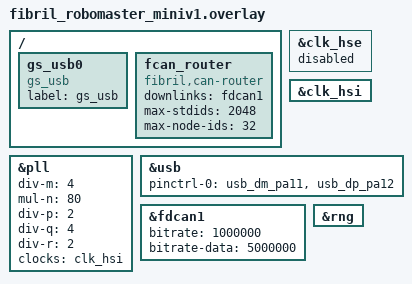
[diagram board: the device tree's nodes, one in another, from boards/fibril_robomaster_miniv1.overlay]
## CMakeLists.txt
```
# SPDX-License-Identifier: Apache-2.0
#
# Zephyr sample: fibril_can router + latency-probe self node driven over
# CANnectivity's gs_usb uplink. Same wire contract as
# fibril_zephyr/samples/lib/fibril_can/latency_probe_node, but the probe self
# node sits inside a fcan_router device — uplink is USB (gs_usb) and downlink
# is fdcan1. Use this variant when the same MCU also has to gateway a
# physical CAN bus to the host.
#
# Prerequisites: see the fibril_can module's zephyr/cmake/fcan_invoke_codegen.cmake
# for the fcan_codegen CLI resolution.

cmake_minimum_required(VERSION 3.20.0)
find_package(Zephyr REQUIRED HINTS $ENV{ZEPHYR_BASE})

project(fibril_can_router_gs_usb_latency_probe LANGUAGES C)

if(NOT ZEPHYR_FIBRIL_CAN_MODULE_DIR)
  message(FATAL_ERROR
    "ZEPHYR_FIBRIL_CAN_MODULE_DIR is not set — is the fibril_can module on "
    "the west manifest and is CONFIG_FIBRIL_CAN=y?")
endif()

include(${ZEPHYR_FIBRIL_CAN_MODULE_DIR}/zephyr/cmake/fcan_invoke_codegen.cmake)

set(FCAN_LATENCY_PROBE_SCHEMA
  "${ZEPHYR_FIBRIL_CAN_MODULE_DIR}/fibril_can_benchmark/schema/latency_probe.yaml"
  CACHE FILEPATH "Schema YAML to feed into fcan_codegen")

fcan_invoke_codegen(
  SCHEMA     "${FCAN_LATENCY_PROBE_SCHEMA}"
  OUTPUT_DIR "${CMAKE_CURRENT_BINARY_DIR}/schema_gen"
  BASE_NAME  schema_gen)

target_sources(app PRIVATE
  src/main.c
  src/probe_logic.c
  src/usbd_setup.c)

target_include_directories(app PRIVATE
  ${CMAKE_CURRENT_SOURCE_DIR}/src)
```

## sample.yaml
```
sample:
  name: fibril_can router + latency-probe self via CANnectivity gs_usb uplink
  description: >-
    fibril_can_benchmark latency-probe firmware wired into a fcan_router self
    node. The router uplink is CANnectivity's gs_usb device class (USB), so
    the host PC opens one SocketCAN interface and the ROS probe launch talks
    to the self node through it. The downlink (fdcan1) stays available for
    real slaves on a physical CAN bus. Same on-wire contract as
    samples/lib/fibril_can/latency_probe_node, but placed at the router
    uplink instead of a bare CAN interface — see firmware-requirements §8.

tests:
  sample.lib.fibril_can.router_gs_usb_latency_probe:
    tags:
      - fibril_can
      - fibril_can_benchmark
      - can
      - router
      - usb
    filter: CONFIG_FIBRIL_CAN and dt_compat_enabled("fibril,can-router") and dt_compat_enabled("gs_usb")
    harness: console
    harness_config:
      type: multi_line
      ordered: true
      regex:
        - "fcan_router_latency_probe: fcan_init OK"
        - "fcan_router_latency_probe: fcan_router_attach_self OK"
        - "fcan_router_latency_probe: fcan_register_all OK"
        - "fcan_router_latency_probe: gs_usb_register OK"
        - "fcan_router_latency_probe: usbd_enable OK"
        - "fcan_router_latency_probe: entering main loop"
    integration_platforms:
      - fibril_robomaster_miniv1
    # Twister needs to know where fcan_codegen lives before it can build this
    # sample. Set FCAN_CODEGEN in the environment before invoking twister:
    #   FCAN_CODEGEN=/abs/path/fcan_codegen twister -T fibril_zephyr/samples/lib/fibril_can/router_gs_usb_latency_probe
    # or pass --extra-args=-DFCAN_CODEGEN=... to twister directly.
```

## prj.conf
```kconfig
# SPDX-License-Identifier: Apache-2.0

# --- fibril_can slave runtime + router driver
CONFIG_FIBRIL_CAN=y
CONFIG_CAN=y
CONFIG_CAN_FD_MODE=y
CONFIG_CAN_FCAN_ROUTER=y

# --- event-driven scheduler wake for fcan_zephyr_can_hal. This sample drives
#     fcan_poll(self) through the router thread (no fcan_zephyr_can_hal
#     instance), so the option has no runtime effect here; kept aligned with
#     the other fibril_can samples so the switch is uniform across the tree.
CONFIG_FCAN_ZEPHYR_EVENT_WAKE=y

# --- Router poll cadence. Default 1000 µs bounds the change-driven echo dwell
#     between "commit" (main thread) and "emit" (router thread) — see the
#     README's "latency components" section. Lowering this reduces average
#     dwell at the cost of CPU spent on empty polls; the effective resolution
#     floor is one SYS_CLOCK_TICKS_PER_SEC tick (100 µs at 10 kHz).
CONFIG_CAN_FCAN_ROUTER_POLL_INTERVAL_US=1000

# --- entropy for boot_id (SPEC §5.3 T_listen jitter seed).
CONFIG_ENTROPY_GENERATOR=y

# --- runtime allocation. K_HEAP_DEFINE in main.c carves its own arena, but
#     leave a small system heap for the CAN / USB / RNG drivers.
CONFIG_HEAP_MEM_POOL_SIZE=4096
CONFIG_MAIN_STACK_SIZE=4096

# --- kernel tick precision. 10 kHz keeps the main tick jitter within the
#     §5 hot-path budget (echo commit dwell ≤ 100 μs @ 1 kHz tick).
CONFIG_SYS_CLOCK_TICKS_PER_SEC=10000

# --- USB device stack next + CANnectivity's gs_usb class. CONFIG_USBD_GS_USB
#     defaults to y whenever a "gs_usb" DT node is enabled, but state it
#     explicitly so the sample's intent is grep-able.
CONFIG_USB_DEVICE_STACK_NEXT=y
CONFIG_USBD_GS_USB=y

# Quieter USB stack — switch the two lines below to _DBG when debugging USB
# enumeration failures on real hardware.
CONFIG_UDC_DRIVER_LOG_LEVEL_WRN=y
CONFIG_USBD_LOG_LEVEL_WRN=y
CONFIG_USBD_GS_USB_LOG_LEVEL_INF=y

# --- logging: no LOG in the hot path (status thread only), so IMMEDIATE
#     mode is safe.
CONFIG_LOG=y
CONFIG_LOG_MODE_IMMEDIATE=y
CONFIG_BOOT_BANNER=y
```

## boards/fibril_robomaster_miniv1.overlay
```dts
/*
 * SPDX-License-Identifier: Apache-2.0
 *
 * router+latency-probe self+gs_usb sample on the Fibril RoboMaster Mini V1.
 *   uplink   = USB FS (PA11/PA12) -> gs_usb subsys -> fcan_router device
 *   downlink = FDCAN1 (PD0/PD1)   (board DTS already sets pinctrl + PLL_Q clock)
 *
 * Mirrors samples/lib/fibril_can/router_gs_usb_self.overlay so both samples
 * share the same host udev/gs_usb setup — see that overlay's comments for
 * the HSI16/PLL rationale. Only the compatible strings and app source
 * differ between the two samples.
 */

/ {
	gs_usb0: gs_usb0 {
		compatible = "gs_usb";
		label = "gs_usb";
	};

	fcan_router: fcan_router {
		compatible = "fibril,can-router";
		status = "okay";
		downlinks = <&fdcan1>;
		/* std_id 学習テーブルの幅。fibril_can_bridge の StdIdAllocator は
		 * 0x100 (256) から発番するので、max-stdids は必ず 0x100 より
		 * 大きい必要がある。DT binding のデフォルト 2048 (= 11-bit CAN
		 * ID 全域) を使う。stdid_mask はエントリあたり 1 バイトなので
		 * 2 KiB。H723 の RAM 予算では誤差。 */
		max-stdids = <2048>;
		max-node-ids = <32>;
	};
};

&clk_hse {
	status = "disabled";
};

&clk_hsi {
	status = "okay";
};

&pll {
	div-m = <4>;
	mul-n = <80>;
	div-p = <2>;
	div-q = <4>;
	div-r = <2>;
	clocks = <&clk_hsi>;
	status = "okay";
};

zephyr_udc0: &usb {
	pinctrl-0 = <&usb_dm_pa11 &usb_dp_pa12>;
	pinctrl-names = "default";
	status = "okay";
};

&fdcan1 {
	/* 1 Mbps arbitration / 5 Mbps FD data phase — matches the single-bus
	 * latency_probe_node sample so wire timings are directly comparable. */
	bitrate = <1000000>;
	bitrate-data = <5000000>;
	status = "okay";
};

&rng {
	status = "okay";
};
```

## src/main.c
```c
/*
 * SPDX-License-Identifier: Apache-2.0
 *
 * Zephyr entry point for the fibril_can router + latency-probe self node +
 * gs_usb sample. Cross-references:
 *
 *   fibril_can_benchmark/docs/firmware-requirements.md — wire contract
 *   fibril_can/docs/09-router.md                        — router lifecycle
 *   samples/lib/fibril_can/router_gs_usb_self           — non-benchmark twin
 *   samples/lib/fibril_can/latency_probe_node           — single-bus twin
 *
 * Threading model
 * ---------------
 * The router driver thread owns fcan_router_on_rx() and calls
 * fcan_poll(self) at CONFIG_CAN_FCAN_ROUTER_POLL_INTERVAL_US granularity.
 * This main thread only calls probe_logic_tick() (topic begin/commit/read,
 * all seqlock-protected). Do NOT add fcan_svc_* calls here — they would
 * race the router thread's fcan_service_poll() slots.
 *
 * Latency vs the single-bus sample
 * --------------------------------
 * The single-bus sample (samples/lib/fibril_can/latency_probe_node) can pin
 * commit → emit into a single tick via the §3.4.1 "on_tick before fcan_poll"
 * order. Here the two are on different threads, so a commit dwell of ~one
 * CONFIG_CAN_FCAN_ROUTER_POLL_INTERVAL_US is intrinsic. Lower that Kconfig
 * to trade CPU for dwell.
 *
 * What this sample does NOT verify
 * --------------------------------
 * - End-to-end against fibril_can_bridge or fibril_can_web; that setup is
 *   the same as the router_gs_usb_self README.
 * - Downlink physical CAN latency budgets. This sample terminates the probe
 *   at the uplink; a probe running on a slave attached to fdcan1 would add
 *   the downlink bus time.
 */

#include <stdint.h>
#include <string.h>

#include <zephyr/device.h>
#include <zephyr/drivers/can.h>
#include <zephyr/kernel.h>
#include <zephyr/logging/log.h>
#include <zephyr/random/random.h>
#include <zephyr/sys/time_units.h>

#include <cannectivity/usb/class/gs_usb.h>

#include <fibril_can/fcan.h>
#include <fibril_can/fcan_protocol.h>
#include <fibril_can/router/fcan_router.h>
#include <fibril_can_zephyr/can_router.h>

#include "schema_gen.h"
#include "probe_logic.h"
#include "usbd_setup.h"

extern const uint8_t  fcan_schema_blob[];
extern const size_t   fcan_schema_blob_len;
extern const uint64_t fcan_schema_hash;

LOG_MODULE_REGISTER(fcan_router_latency_probe, LOG_LEVEL_INF);

#define ROUTER_NODE DT_NODELABEL(fcan_router)
#define ROUTER_DEV  DEVICE_DT_GET(ROUTER_NODE)

/* §6 default; probe launch expects --node-id 0x20. Override via
 * -DCONFIG_EXTRA_CFLAGS=-DNODE_ID=0x?? when running two boards side by side. */
#ifndef NODE_ID
#define NODE_ID     0x20
#endif

#define MASTER_LOST_US 0U  /* §7 — disabled so echo never stalls. */

#ifndef TICK_HZ
#define TICK_HZ     1000U
#endif

K_HEAP_DEFINE(fcan_heap, 16 * 1024);

static void *heap_alloc(size_t size, size_t align, void *ctx)
{
	ARG_UNUSED(ctx);
	return k_heap_aligned_alloc(&fcan_heap, align, size, K_NO_WAIT);
}

static const char *state_str(fcan_node_state_t s)
{
	switch (s) {
	case FCAN_STATE_UNPROVISIONED: return "UNPROVISIONED";
	case FCAN_STATE_PROVISIONED:   return "PROVISIONED";
	case FCAN_STATE_RUNNING:       return "RUNNING";
	case FCAN_STATE_FAULT:         return "FAULT";
	default:                       return "?";
	}
}

/* Handed to the status thread after bring-up. Reads happen from a lower
 * priority thread; the values themselves are word-sized so a torn read is
 * at worst a one-cycle stale counter in the log line. */
static fcan_node_t     *g_self;
static fcan_router_t   *g_router;
static const struct device *g_router_dev;

static void status_thread_entry(void *a, void *b, void *c)
{
	ARG_UNUSED(a);
	ARG_UNUSED(b);
	ARG_UNUSED(c);

	fcan_node_state_t last = FCAN_STATE_UNPROVISIONED;
	while (true) {
		if (g_self != NULL && g_router != NULL && g_router_dev != NULL) {
			const fcan_node_state_t s = fcan_state(g_self);
			if (s != last) {
				LOG_INF("state: %s -> %s (fault=%d)",
					state_str(last), state_str(s),
					(int)fcan_fault(g_self));
				last = s;
			}
			fcan_router_diag_t d;
			fcan_router_get_diag(g_router, &d);
			uint32_t ing_drops =
				fcan_router_zephyr_ingress_drops(g_router_dev);
			/* drop_unknown_stdid > 0 かつ learned_stdids=0 は
			 * 「max-stdids が bridge 発番 (>=0x100) を吸収できていない」
			 * サイン。overlay の max-stdids を確認する。 */
			LOG_INF("alive: state=%s up->dn[0]=%u dn->up[0]=%u "
				"drop_send=%u ingress=%u "
				"drop_unk_stdid=%u drop_ovfl=%u learned_stdids=%u",
				state_str(s),
				d.fwd_up_to_down[0], d.fwd_down_to_up[0],
				d.drop_send_failed, ing_drops,
				d.drop_unknown_stdid, d.drop_table_overflow,
				d.learned_stdids);
		}
		k_sleep(K_SECONDS(1));
	}
}
K_THREAD_DEFINE(status_tid, 1024, status_thread_entry, NULL, NULL, NULL,
		7, 0, 0);

int main(void)
{
	const struct device *router = ROUTER_DEV;
	const struct device *gs_usb = DEVICE_DT_GET(DT_NODELABEL(gs_usb0));

	if (!device_is_ready(router)) {
		LOG_ERR("router device %s not ready", router->name);
		return -ENODEV;
	}

	fcan_router_t *r = fcan_router_zephyr_get(router);
	if (r == NULL) {
		LOG_ERR("fcan_router_zephyr_get returned NULL (init failed)");
		return -ENODEV;
	}

	fcan_node_t *self = k_heap_aligned_alloc(&fcan_heap, 8,
						 fcan_node_storage_size(),
						 K_NO_WAIT);
	if (self == NULL) {
		LOG_ERR("fcan_heap OOM allocating node (%u bytes)",
			(unsigned)fcan_node_storage_size());
		return -ENOMEM;
	}

	static const uint8_t counts[] = {1U};
	BUILD_ASSERT(ARRAY_SIZE(counts) == FCAN_NUM_BLOCK_ARRAYS,
		     "counts[] must match the schema's block-array count");

	fcan_config_t cfg = {
		.node_id = NODE_ID,
		.boot_id = sys_rand32_get(),
		.schema_blob = fcan_schema_blob,
		.schema_blob_len = (uint16_t)fcan_schema_blob_len,
		.schema_hash = fcan_schema_hash,
		.protocol_version = FCAN_PROTOCOL_VERSION,
		.block_count = FCAN_NUM_BLOCK_ARRAYS,
		.instance_counts = counts,
		.limits = {
			.max_frames = FCAN_MAX_FRAMES,
			.max_copy_entries = FCAN_MAX_COPY_ENTRIES,
			.service_buffer = FCAN_SERVICE_BUFFER,
			.service_reassembly = FCAN_SERVICE_REASSEMBLY,
		},
		/* HAL comes from the router: fcan_poll(self) TX goes to the
		 * router's uplink (gs_usb), and fcan_router_on_rx() feeds
		 * uplink frames back into self. */
		.hal = fcan_router_get_self_hal(r),
		.allocator = {.alloc = heap_alloc, .ctx = NULL},
		.master_lost_us = MASTER_LOST_US,
	};
	fcan_apply_schema_capacities(&cfg.limits, counts);

	if (fcan_init(self, &cfg) != FCAN_OK) {
		LOG_ERR("fcan_init failed (fault=%d)", (int)fcan_fault(self));
		return -EIO;
	}
	LOG_INF("fcan_init OK: node_id=0x%02x schema_hash=0x%016llx blob_len=%u tick=%u Hz",
		cfg.node_id, (unsigned long long)fcan_schema_hash,
		(unsigned)fcan_schema_blob_len, (unsigned)TICK_HZ);

	/* Attach BEFORE the host can open the gs_usb channel — see
	 * docs/09-router.md for why the router thread must not see frames
	 * before the self node is wired in. */
	if (fcan_router_attach_self(r, self) != FCAN_OK) {
		LOG_ERR("fcan_router_attach_self failed (fault=%d)",
			(int)fcan_fault(self));
		return -EIO;
	}
	LOG_INF("fcan_router_attach_self OK");

	if (fcan_register_all(self) != FCAN_OK) {
		LOG_ERR("fcan_register_all failed (fault=%d)",
			(int)fcan_fault(self));
		return -EIO;
	}
	LOG_INF("fcan_register_all OK");

	probe_logic_init();

	if (!device_is_ready(gs_usb)) {
		LOG_ERR("gs_usb device %s not ready", gs_usb->name);
		return -ENODEV;
	}

	int rc = usbd_setup_init();
	if (rc != 0) {
		LOG_ERR("usbd_setup_init failed (%d)", rc);
		return rc;
	}

	const struct device *channels[] = {router};
	rc = gs_usb_register(gs_usb, channels, ARRAY_SIZE(channels), NULL, NULL);
	if (rc != 0) {
		LOG_ERR("gs_usb_register failed (%d)", rc);
		return rc;
	}
	LOG_INF("gs_usb_register OK (1 channel: %s)", router->name);

	rc = usbd_setup_enable();
	if (rc != 0) {
		return rc;
	}
	LOG_INF("usbd_enable OK");

	g_self = self;
	g_router = r;
	g_router_dev = router;

	LOG_INF("entering main loop");

	const int64_t period_ticks =
		(int64_t)k_us_to_ticks_ceil64(1000000ULL / TICK_HZ);
	int64_t next = k_uptime_ticks();
	while (true) {
		probe_logic_tick();

		next += period_ticks;
		k_sleep(K_TIMEOUT_ABS_TICKS(next));
	}
	/* unreachable */
}
```

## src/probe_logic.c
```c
/*
 * SPDX-License-Identifier: Apache-2.0
 *
 * Router-variant tick logic. On-wire behaviour is identical to
 * samples/lib/fibril_can/latency_probe_node/src/probe_logic.c — the fcan
 * topic begin/commit/read API is seqlock-protected so it is safe to call
 * from the app thread while the router driver thread runs fcan_poll(self)
 * asynchronously.
 *
 * Firmware-requirements alignment mirrors the single-bus sample:
 *
 *   §3.1  seq / t_master_send_ns copied inside the same app tick as the ping
 *         arrival. The "arrival" event lands in router-thread context
 *         (fcan_router_on_rx forwards uplink frames into self); the app
 *         tick reads the up-to-date state via latencyprobe_ping_read.
 *   §3.2  ticks with no ping yet emit zeros so the probe can filter warmup
 *         samples by seq == 0.
 *   §3.4  periodic echo fires every tick; the runtime scheduler running
 *         inside fcan_poll(self) on the router thread handles next_due gating.
 *   §4    t_slave_*_us stamped in app-tick context — the requirement only
 *         asks for a monotonic microsecond source, not for a common clock
 *         with any other component of the pipeline.
 *
 * No heap, no logging, no floating point (§5).
 */

#include "probe_logic.h"

#include <stdbool.h>
#include <stdint.h>

#include <zephyr/kernel.h>
#include <zephyr/sys/time_units.h>

#include "schema_gen.h"

#define PROBE_INST 0U

static uint32_t last_committed_seq;
static bool     any_committed;

static inline uint32_t now_us(void)
{
	return k_cyc_to_us_floor32(k_cycle_get_32());
}

void probe_logic_init(void)
{
	last_committed_seq = 0U;
	any_committed = false;
}

void probe_logic_tick(void)
{
	latencyprobe_ping_t ping;
	const bool got_ping = latencyprobe_ping_read(PROBE_INST, &ping);
	const uint32_t t_recv = got_ping ? now_us() : 0U;

	latencyprobe_echo_t *out = latencyprobe_echo_begin(PROBE_INST);
	if (out != NULL) {
		if (got_ping) {
			out->seq = ping.seq;
			out->t_master_send_ns = ping.t_master_send_ns;
			out->t_slave_recv_us = t_recv;
		} else {
			out->seq = 0U;
			out->t_master_send_ns = 0U;
			out->t_slave_recv_us = 0U;
		}
		out->t_slave_send_us = now_us();
		latencyprobe_echo_commit(PROBE_INST);
	}

	if (got_ping && (!any_committed || ping.seq != last_committed_seq)) {
		latencyprobe_echo_change_t *chg = latencyprobe_echo_change_begin(PROBE_INST);
		if (chg != NULL) {
			chg->seq = ping.seq;
			chg->t_master_send_ns = ping.t_master_send_ns;
			chg->t_slave_recv_us = t_recv;
			chg->t_slave_send_us = now_us();
			latencyprobe_echo_change_commit(PROBE_INST);
		}
		last_committed_seq = ping.seq;
		any_committed = true;
	}
}
```

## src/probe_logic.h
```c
/*
 * SPDX-License-Identifier: Apache-2.0
 */
#ifndef ROUTER_LATENCY_PROBE_LOGIC_H_
#define ROUTER_LATENCY_PROBE_LOGIC_H_

void probe_logic_init(void);

/* Same-tick copy of the latest ping into echo (periodic) and echo_change
 * (app-trigger). In the router variant this runs on the app thread; the
 * router driver thread runs fcan_poll(self) asynchronously (see main.c
 * for the threading model — the two loops are decoupled at
 * CONFIG_CAN_FCAN_ROUTER_POLL_INTERVAL_US granularity). */
void probe_logic_tick(void);

#endif /* ROUTER_LATENCY_PROBE_LOGIC_H_ */
```

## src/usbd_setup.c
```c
/*
 * SPDX-License-Identifier: Apache-2.0
 *
 * usbd_next boilerplate for the router+latency-probe+gs_usb sample. Copy of
 * samples/lib/fibril_can/router_gs_usb_self/src/usbd_setup.c with a
 * differentiating product string; keeping the VID/PID identical means the
 * same host-side udev rules and gs_usb pid filters catch either firmware.
 */

#include "usbd_setup.h"

#include <zephyr/logging/log.h>
#include <zephyr/usb/usbd.h>

LOG_MODULE_REGISTER(usbd_setup, LOG_LEVEL_INF);

#define GS_USB_CLASS_INSTANCE_NAME "gs_usb_0"

/* VID/PID/manufacturer match CANnectivity's Kconfig defaults so pre-existing
 * host-side rules apply. The product string is the only differentiator. */
#define ROUTER_GS_USB_PROBE_VID          0x1209U
#define ROUTER_GS_USB_PROBE_PID          0xca01U
#define ROUTER_GS_USB_PROBE_MANUFACTURER "CANnectivity"
#define ROUTER_GS_USB_PROBE_PRODUCT      "CANnectivity USB to CAN adapter (latency probe)"
#define ROUTER_GS_USB_PROBE_MAX_POWER    125U /* 250 mA (bMaxPower is in 2 mA units) */

USBD_DEVICE_DEFINE(usbd, DEVICE_DT_GET(DT_NODELABEL(zephyr_udc0)),
		   ROUTER_GS_USB_PROBE_VID, ROUTER_GS_USB_PROBE_PID);

USBD_DESC_LANG_DEFINE(lang);
USBD_DESC_MANUFACTURER_DEFINE(mfr, ROUTER_GS_USB_PROBE_MANUFACTURER);
USBD_DESC_PRODUCT_DEFINE(product, ROUTER_GS_USB_PROBE_PRODUCT);
USBD_DESC_SERIAL_NUMBER_DEFINE(sn);
USBD_DESC_CONFIG_DEFINE(fs_config_desc, "Full-Speed Configuration");

USBD_CONFIGURATION_DEFINE(fs_config, USB_SCD_SELF_POWERED,
			  ROUTER_GS_USB_PROBE_MAX_POWER, &fs_config_desc);

int usbd_setup_init(void)
{
	int err;

	err = usbd_add_descriptor(&usbd, &lang);
	if (err != 0) {
		LOG_ERR("usbd_add_descriptor(lang) failed (%d)", err);
		return err;
	}

	err = usbd_add_descriptor(&usbd, &mfr);
	if (err != 0) {
		LOG_ERR("usbd_add_descriptor(mfr) failed (%d)", err);
		return err;
	}

	err = usbd_add_descriptor(&usbd, &product);
	if (err != 0) {
		LOG_ERR("usbd_add_descriptor(product) failed (%d)", err);
		return err;
	}

	err = usbd_add_descriptor(&usbd, &sn);
	if (err != 0) {
		LOG_ERR("usbd_add_descriptor(sn) failed (%d)", err);
		return err;
	}

	err = usbd_add_configuration(&usbd, USBD_SPEED_FS, &fs_config);
	if (err != 0) {
		LOG_ERR("usbd_add_configuration(fs) failed (%d)", err);
		return err;
	}

	err = usbd_register_class(&usbd, GS_USB_CLASS_INSTANCE_NAME,
				  USBD_SPEED_FS, 1);
	if (err != 0) {
		LOG_ERR("usbd_register_class(gs_usb_0) failed (%d)", err);
		return err;
	}

	err = usbd_device_set_code_triple(&usbd, USBD_SPEED_FS, 0, 0, 0);
	if (err != 0) {
		LOG_ERR("usbd_device_set_code_triple(fs) failed (%d)", err);
		return err;
	}

	err = usbd_device_set_bcd_usb(&usbd, USBD_SPEED_FS, USB_SRN_2_0_1);
	if (err != 0) {
		LOG_ERR("usbd_device_set_bcd_usb(fs) failed (%d)", err);
		return err;
	}

	err = usbd_init(&usbd);
	if (err != 0) {
		LOG_ERR("usbd_init failed (%d)", err);
		return err;
	}

	return 0;
}

int usbd_setup_enable(void)
{
	int err = usbd_enable(&usbd);

	if (err != 0) {
		LOG_ERR("usbd_enable failed (%d)", err);
	}
	return err;
}
```

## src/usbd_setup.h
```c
/*
 * SPDX-License-Identifier: Apache-2.0
 *
 * Minimal usbd_next boilerplate for the router+latency-probe+gs_usb sample.
 * A cut-down of CANnectivity's app/src/usb.c: full-speed only, no DFU, no
 * MSOSV2 descriptor set. The registered gs_usb class instance
 * ("gs_usb_0") is the same one CANnectivity registers, so host-side udev
 * rules that already work with CANnectivity dongles work here too.
 *
 * The VID/PID pair matches CANnectivity's defaults (0x1209:0xca01); only
 * the product string differs so `lsusb -v` distinguishes this firmware
 * from the router_gs_usb_self sample when both are on the bench.
 */

#ifndef ROUTER_GS_USB_LATENCY_PROBE_USBD_SETUP_H_
#define ROUTER_GS_USB_LATENCY_PROBE_USBD_SETUP_H_

#ifdef __cplusplus
extern "C" {
#endif

/* Register descriptors + full-speed configuration + the "gs_usb_0" class
 * instance, then call usbd_init(). Does NOT enable the device — the caller
 * must first bind CAN channels via gs_usb_register() and only then call
 * usbd_setup_enable(). Returns 0 on success, a negative errno on failure. */
int usbd_setup_init(void);

/* Enable the previously-initialised USB device. Splitting this from init lets
 * the sample attach the router self node BEFORE the host can enumerate. */
int usbd_setup_enable(void);

#ifdef __cplusplus
}
#endif

#endif /* ROUTER_GS_USB_LATENCY_PROBE_USBD_SETUP_H_ */
```
